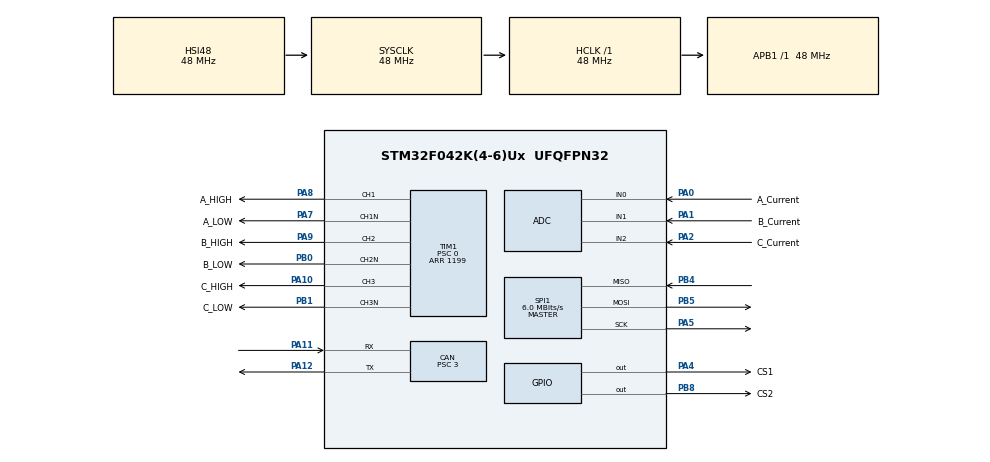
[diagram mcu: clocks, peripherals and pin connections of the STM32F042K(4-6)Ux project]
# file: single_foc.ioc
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ADC.DMAContinuousRequests=ENABLE
ADC.DiscontinuousConvMode=DISABLE
ADC.ExternalTrigConv=ADC_EXTERNALTRIGCONV_T1_TRGO
ADC.ExternalTrigConvEdge=ADC_EXTERNALTRIGCONVEDGE_RISING
ADC.SamplingTime=ADC_SAMPLETIME_7CYCLES_5
CAN.CalculateBaudRate=1000000
CAN.CalculateTimeBit=1000
CAN.BS1=CAN_BS1_13TQ
CAN.BS2=CAN_BS2_2TQ
CAN.CalculateTimeQuantum=62.5
CAN.Prescaler=3
Dma.ADC.0.Direction=DMA_PERIPH_TO_MEMORY
Dma.ADC.0.Instance=DMA1_Channel1
Dma.ADC.0.MemDataAlignment=DMA_MDATAALIGN_HALFWORD
Dma.ADC.0.MemInc=DMA_MINC_ENABLE
Dma.ADC.0.Mode=DMA_CIRCULAR
Dma.ADC.0.PeriphDataAlignment=DMA_PDATAALIGN_HALFWORD
Dma.ADC.0.PeriphInc=DMA_PINC_DISABLE
Dma.ADC.0.Priority=DMA_PRIORITY_LOW
Dma.Request0=ADC
Mcu.Family=STM32F0
Mcu.Name=STM32F042K(4-6)Ux
Mcu.Package=UFQFPN32
NVIC.ADC1_IRQn=true\:0\:0\:false\:false\:true\:true\:true\:true
NVIC.DMA1_Channel1_IRQn=true\:0\:0\:false\:false\:true\:false\:true\:true
NVIC.SPI1_IRQn=true\:0\:0\:false\:false\:true\:true\:true\:true
NVIC.TIM1_BRK_UP_TRG_COM_IRQn=true\:0\:0\:false\:false\:true\:true\:true\:true
PA0.GPIO_Label=A_Current
PA0.Mode=IN0
PA0.Signal=ADC_IN0
PA1.GPIO_Label=B_Current
PA1.Mode=IN1
PA1.Signal=ADC_IN1
PA10.GPIO_Label=C_HIGH
PA10.Signal=S_TIM1_CH3
PA11.Mode=CAN_Activate
PA11.Signal=CAN_RX
PA12.Mode=CAN_Activate
PA12.Signal=CAN_TX
PA13.Mode=Serial_Wire
PA13.Signal=SYS_SWDIO
PA14.Mode=Serial_Wire
PA14.Signal=SYS_SWCLK
PA2.GPIO_Label=C_Current
PA2.Mode=IN2
PA2.Signal=ADC_IN2
PA4.GPIO_Label=CS1
PA4.GPIO_ModeDefaultOutputPP=GPIO_MODE_OUTPUT_PP
PA4.GPIO_PuPd=GPIO_PULLUP
PA4.GPIO_Speed=GPIO_SPEED_FREQ_MEDIUM
PA4.PinState=GPIO_PIN_SET
PA4.Signal=GPIO_Output
PA5.Mode=Full_Duplex_Master
PA5.Signal=SPI1_SCK
PA7.GPIO_Label=A_LOW
PA7.Mode=PWM Generation1 CH1 CH1N
PA7.Signal=TIM1_CH1N
PA8.GPIO_Label=A_HIGH
PA8.Signal=S_TIM1_CH1
PA9.GPIO_Label=B_HIGH
PA9.Signal=S_TIM1_CH2
PB0.GPIO_Label=B_LOW
PB0.Mode=PWM Generation2 CH2 CH2N
PB0.Signal=TIM1_CH2N
PB1.GPIO_Label=C_LOW
PB1.Mode=PWM Generation3 CH3 CH3N
PB1.Signal=TIM1_CH3N
PB4.Mode=Full_Duplex_Master
PB4.Signal=SPI1_MISO
PB5.Mode=Full_Duplex_Master
PB5.Signal=SPI1_MOSI
PB8.GPIO_Label=CS2
PB8.GPIO_PuPd=GPIO_PULLUP
PB8.PinState=GPIO_PIN_SET
PB8.Signal=GPIO_Output
ProjectManager.HeapSize=0x200
ProjectManager.StackSize=0x400
ProjectManager.TargetToolchain=STM32CubeIDE
RCC.AHBFreq_Value=48000000
RCC.APB1Freq_Value=48000000
RCC.APB1TimFreq_Value=48000000
RCC.HCLKFreq_Value=48000000
RCC.SYSCLKFreq_VALUE=48000000
RCC.SYSCLKSource=RCC_SYSCLKSOURCE_HSI48
SH.S_TIM1_CH1.0=TIM1_CH1,PWM Generation1 CH1 CH1N
SH.S_TIM1_CH2.0=TIM1_CH2,PWM Generation2 CH2 CH2N
SH.S_TIM1_CH3.0=TIM1_CH3,PWM Generation3 CH3 CH3N
SPI1.BaudRatePrescaler=SPI_BAUDRATEPRESCALER_8
SPI1.CLKPhase=SPI_PHASE_2EDGE
SPI1.CalculateBaudRate=6.0 MBits/s
SPI1.DataSize=SPI_DATASIZE_16BIT
SPI1.Direction=SPI_DIRECTION_2LINES
SPI1.Mode=SPI_MODE_MASTER
SPI1.VirtualType=VM_MASTER
TIM1.Channel-PWM\ Generation1\ CH1\ CH1N=TIM_CHANNEL_1
TIM1.Channel-PWM\ Generation2\ CH2\ CH2N=TIM_CHANNEL_2
TIM1.Channel-PWM\ Generation3\ CH3\ CH3N=TIM_CHANNEL_3
TIM1.CounterMode=TIM_COUNTERMODE_CENTERALIGNED1
TIM1.DeadTime=10
TIM1.Period=1199
TIM1.Prescaler=0
TIM1.RepetitionCounter=1
TIM1.TIM_MasterOutputTrigger=TIM_TRGO_OC4REF
TIM1.TIM_MasterSlaveMode=TIM_MASTERSLAVEMODE_DISABLE
board=custom

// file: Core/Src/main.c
/* USER CODE BEGIN Header */
/**
  ******************************************************************************
  * @file           : main.c
  * @brief          : Main program body
  ******************************************************************************
  * @attention
  *
  * Copyright (c) 2026 STMicroelectronics.
  * All rights reserved.
  *
  * This software is licensed under terms that can be found in the LICENSE file
  * in the root directory of this software component.
  * If no LICENSE file comes with this software, it is provided AS-IS.
  *
  ******************************************************************************
  */
/* USER CODE END Header */
#include "main.h"
#include "adc.h"
#include "can.h"
#include "dma.h"
#include "spi.h"
#include "tim.h"
#include "gpio.h"

/* USER CODE BEGIN Includes */
#include "AS5147P.h"
#include "can_protocol.h"
#include "foc_control.h"
#include "foc_fast.h"
/* USER CODE END Includes */

/* USER CODE BEGIN PV */
AS5147P_Handle_t AS5147P_handle_1;
/* For debugging, watch g_foc_fast (foc_fast.h) in Live Expressions: currents,
 * encoder angle/position, faults and loop timing are all there. */
/* USER CODE END PV */

void SystemClock_Config(void);

int main(void)
{

  /* MCU Configuration--------------------------------------------------------*/

  /* Reset of all peripherals, Initializes the Flash interface and the Systick. */
  HAL_Init();

  /* Configure the system clock */
  SystemClock_Config();

  /* Initialize all configured peripherals */
  MX_GPIO_Init();
  MX_DMA_Init();
  MX_SPI1_Init();
  MX_ADC_Init();
  MX_TIM1_Init();
  MX_CAN_Init();
  /* USER CODE BEGIN 2 */
  /* Starts the 20 kHz fast loop and 2 kHz slow loop (both interrupt driven).
   * The bridge stays off until a CAN "enter motor mode" command. */
  FocControl_Init();
  CanProto_Init(FocControl_GetCanId());
  /* USER CODE END 2 */

  /* Infinite loop */
  while (1)
  {

    /* USER CODE BEGIN 3 */
    CanProto_Poll();
    FocControl_Background();

  }
  /* USER CODE END 3 */
}

void SystemClock_Config(void)
{
  RCC_OscInitTypeDef RCC_OscInitStruct = {0};
  RCC_ClkInitTypeDef RCC_ClkInitStruct = {0};

  /** Initializes the RCC Oscillators according to the specified parameters
  * in the RCC_OscInitTypeDef structure.
  */
  RCC_OscInitStruct.OscillatorType = RCC_OSCILLATORTYPE_HSI14|RCC_OSCILLATORTYPE_HSI48;
  RCC_OscInitStruct.HSI48State = RCC_HSI48_ON;
  RCC_OscInitStruct.HSI14State = RCC_HSI14_ON;
  RCC_OscInitStruct.HSI14CalibrationValue = 16;
  RCC_OscInitStruct.PLL.PLLState = RCC_PLL_NONE;
  if (HAL_RCC_OscConfig(&RCC_OscInitStruct) != HAL_OK)
  {
    Error_Handler();
  }

  /** Initializes the CPU, AHB and APB buses clocks
  */
  RCC_ClkInitStruct.ClockType = RCC_CLOCKTYPE_HCLK|RCC_CLOCKTYPE_SYSCLK
                              |RCC_CLOCKTYPE_PCLK1;
  RCC_ClkInitStruct.SYSCLKSource = RCC_SYSCLKSOURCE_HSI48;
  RCC_ClkInitStruct.AHBCLKDivider = RCC_SYSCLK_DIV1;
  RCC_ClkInitStruct.APB1CLKDivider = RCC_HCLK_DIV1;

  if (HAL_RCC_ClockConfig(&RCC_ClkInitStruct, FLASH_LATENCY_1) != HAL_OK)
  {
    Error_Handler();
  }
}

void Error_Handler(void)
{
  /* USER CODE BEGIN Error_Handler_Debug */
  /* User can add his own implementation to report the HAL error return state */
  FocFast_EmergencyOff();   /* gates to idle first: never leave the bridge switching */
  __disable_irq();
  while (1)
  {
  }
  /* USER CODE END Error_Handler_Debug */
}
